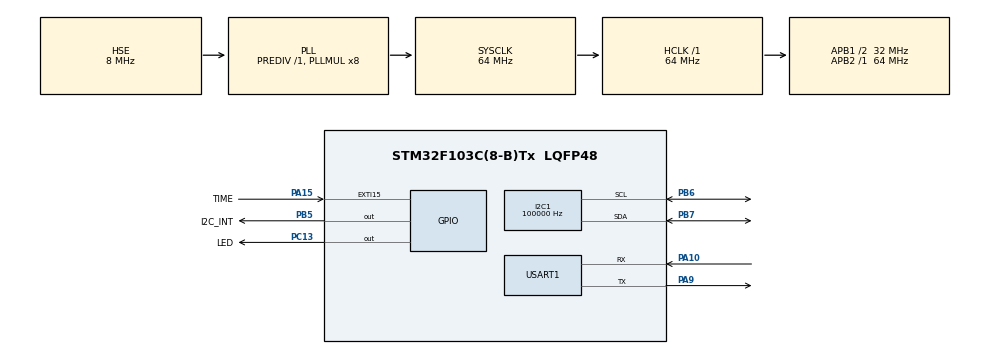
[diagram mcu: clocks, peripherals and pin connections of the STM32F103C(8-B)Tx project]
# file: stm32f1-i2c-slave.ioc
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Mcu.Family=STM32F1
Dma.USART1_TX.2.Direction=DMA_MEMORY_TO_PERIPH
NVIC.DMA1_Channel5_IRQn=true\:0\:0\:false\:false\:true\:false\:true
NVIC.I2C1_EV_IRQn=true\:0\:0\:false\:false\:true\:true\:true
Dma.I2C1_TX.1.Mode=DMA_NORMAL
VP_RTC_VS_RTC_Activate.Mode=RTC_Enabled
Dma.USART1_RX.3.MemDataAlignment=DMA_MDATAALIGN_BYTE
RCC.SYSCLKSource=RCC_SYSCLKSOURCE_PLLCLK
ProjectManager.StackSize=0x400
PD1-OSC_OUT.Signal=RCC_OSC_OUT
Dma.I2C1_TX.1.Direction=DMA_MEMORY_TO_PERIPH
PA15.GPIO_Label=TIME
I2C1.ClockSpeed=100000
PA15.GPIO_ModeDefaultEXTI=GPIO_MODE_IT_FALLING
RCC.HCLKFreq_Value=64000000
RCC.APB2TimFreq_Value=64000000
PB6.Signal=I2C1_SCL
PB5.PinState=GPIO_PIN_SET
Dma.I2C1_RX.0.PeriphDataAlignment=DMA_PDATAALIGN_BYTE
PB6.Mode=I2C
Dma.I2C1_TX.1.PeriphInc=DMA_PINC_DISABLE
RCC.AHBFreq_Value=64000000
Dma.I2C1_RX.0.Priority=DMA_PRIORITY_HIGH
NVIC.EXTI15_10_IRQn=true\:0\:0\:false\:false\:true\:true\:true
Dma.I2C1_RX.0.Mode=DMA_NORMAL
RCC.RTCClockSelection=RCC_RTCCLKSOURCE_LSE
RCC.PLLMUL=RCC_PLL_MUL8
I2C1.NoStretchMode=I2C_NOSTRETCH_DISABLE
PC14-OSC32_IN.Mode=LSE-External-Oscillator
PC13-TAMPER-RTC.PinState=GPIO_PIN_SET
PA14.Mode=Serial_Wire
Dma.USART1_TX.2.PeriphDataAlignment=DMA_PDATAALIGN_BYTE
PB7.Signal=I2C1_SDA
Dma.USART1_RX.3.Direction=DMA_PERIPH_TO_MEMORY
Dma.I2C1_RX.0.Direction=DMA_PERIPH_TO_MEMORY
PC13-TAMPER-RTC.GPIO_Speed=GPIO_SPEED_FREQ_HIGH
Dma.USART1_TX.2.MemDataAlignment=DMA_MDATAALIGN_BYTE
NVIC.I2C1_ER_IRQn=true\:0\:0\:false\:false\:true\:true\:true
Mcu.Package=LQFP48
Dma.USART1_RX.3.Instance=DMA1_Channel5
PA10.Signal=USART1_RX
PA15.Signal=GPXTI15
PB5.GPIO_Speed=GPIO_SPEED_FREQ_HIGH
PB5.GPIO_Label=I2C_INT
Dma.Request2=USART1_TX
Dma.Request1=I2C1_TX
RCC.APB1TimFreq_Value=64000000
Dma.Request3=USART1_RX
NVIC.DMA1_Channel4_IRQn=true\:0\:0\:false\:false\:true\:false\:true
RTC.AutoPrediv=RTC_AUTO_1_SECOND
NVIC.USART1_IRQn=true\:0\:0\:false\:false\:true\:true\:true
Dma.Request0=I2C1_RX
Dma.USART1_RX.3.MemInc=DMA_MINC_ENABLE
Dma.I2C1_TX.1.PeriphDataAlignment=DMA_PDATAALIGN_BYTE
RCC.PLLSourceVirtual=RCC_PLLSOURCE_HSE
PB5.GPIO_ModeDefaultOutputPP=GPIO_MODE_OUTPUT_OD
PC15-OSC32_OUT.Mode=LSE-External-Oscillator
NVIC.DMA1_Channel6_IRQn=true\:0\:0\:false\:false\:true\:false\:true
Dma.I2C1_RX.0.PeriphInc=DMA_PINC_DISABLE
Dma.I2C1_RX.0.MemDataAlignment=DMA_MDATAALIGN_BYTE
PD1-OSC_OUT.Mode=HSE-External-Oscillator
PA10.Mode=Asynchronous
Dma.USART1_TX.2.MemInc=DMA_MINC_ENABLE
Dma.USART1_RX.3.PeriphInc=DMA_PINC_DISABLE
PC13-TAMPER-RTC.Signal=GPIO_Output
PD0-OSC_IN.Signal=RCC_OSC_IN
RCC.APB1CLKDivider=RCC_HCLK_DIV2
PC14-OSC32_IN.Signal=RCC_OSC32_IN
I2C1.DualAddressMode=I2C_DUALADDRESS_DISABLE
PA13.Signal=SYS_JTMS-SWDIO
PA9.Mode=Asynchronous
ProjectManager.TargetToolchain=STM32CubeIDE
PA9.Signal=USART1_TX
Dma.I2C1_RX.0.MemInc=DMA_MINC_ENABLE
Dma.I2C1_TX.1.Instance=DMA1_Channel6
RCC.USBFreq_Value=64000000
PC15-OSC32_OUT.Signal=RCC_OSC32_OUT
PD0-OSC_IN.Mode=HSE-External-Oscillator
board=custom
Dma.I2C1_TX.1.Priority=DMA_PRIORITY_HIGH
PC13-TAMPER-RTC.GPIO_Label=LED
RCC.APB2Freq_Value=64000000
Dma.I2C1_TX.1.MemInc=DMA_MINC_ENABLE
Dma.USART1_TX.2.Priority=DMA_PRIORITY_LOW
Dma.I2C1_TX.1.MemDataAlignment=DMA_MDATAALIGN_BYTE
Dma.USART1_RX.3.PeriphDataAlignment=DMA_PDATAALIGN_BYTE
PA13.Mode=Serial_Wire
Mcu.Name=STM32F103C(8-B)Tx
Dma.USART1_RX.3.Priority=DMA_PRIORITY_LOW
Dma.USART1_TX.2.PeriphInc=DMA_PINC_DISABLE
I2C1.OwnAddress=0x68
RCC.SYSCLKFreq_VALUE=64000000
PC13-TAMPER-RTC.GPIO_ModeDefaultOutputPP=GPIO_MODE_OUTPUT_OD
PB5.Signal=GPIO_Output
PB5.GPIO_PuPd=GPIO_PULLUP
USART1.VirtualMode=VM_ASYNC
PB7.Mode=I2C
PA14.Signal=SYS_JTCK-SWCLK
ProjectManager.HeapSize=0x200
Dma.USART1_TX.2.Mode=DMA_NORMAL
NVIC.PriorityGroup=NVIC_PRIORITYGROUP_4
Dma.USART1_TX.2.Instance=DMA1_Channel4
NVIC.DMA1_Channel7_IRQn=true\:0\:0\:false\:false\:true\:false\:true
RCC.APB1Freq_Value=32000000
Dma.USART1_RX.3.Mode=DMA_NORMAL
Dma.I2C1_RX.0.Instance=DMA1_Channel7

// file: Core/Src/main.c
/* USER CODE BEGIN Header */
/**
  ******************************************************************************
  * @file           : main.c
  * @brief          : Main program body
  ******************************************************************************
  * @attention
  *
  * <h2><center>&copy; Copyright (c) 2020 STMicroelectronics.
  * All rights reserved.</center></h2>
  *
  * This software component is licensed by ST under BSD 3-Clause license,
  * the "License"; You may not use this file except in compliance with the
  * License. You may obtain a copy of the License at:
  *                        opensource.org/licenses/BSD-3-Clause
  *
  ******************************************************************************
  */
/* USER CODE END Header */
#include "main.h"

UART_HandleTypeDef huart1;
DMA_HandleTypeDef hdma_usart1_tx;
DMA_HandleTypeDef hdma_usart1_rx;

void SystemClock_Config(void);
static void MX_GPIO_Init(void);
static void MX_DMA_Init(void);
static void MX_I2C1_Init(void);
static void MX_USART1_UART_Init(void);
static void MX_RTC_Init(void);

/* USER CODE BEGIN 0 */

extern void initialise_monitor_handles(void);
int app_main();
/* USER CODE END 0 */

int main(void)
{
  /* USER CODE BEGIN 1 */
  initialise_monitor_handles();
  /* USER CODE END 1 */

  /* MCU Configuration--------------------------------------------------------*/

  /* Reset of all peripherals, Initializes the Flash interface and the Systick. */
  HAL_Init();

  /* Configure the system clock */
  SystemClock_Config();

  /* Initialize all configured peripherals */
  MX_GPIO_Init();
  MX_DMA_Init();
  MX_I2C1_Init();
  MX_USART1_UART_Init();
  MX_RTC_Init();
  /* USER CODE BEGIN 2 */
  app_main();
  /* USER CODE END 2 */

  /* Infinite loop */

}

void SystemClock_Config(void)
{
  RCC_OscInitTypeDef RCC_OscInitStruct = {0};
  RCC_ClkInitTypeDef RCC_ClkInitStruct = {0};
  RCC_PeriphCLKInitTypeDef PeriphClkInit = {0};

  /** Initializes the RCC Oscillators according to the specified parameters
  * in the RCC_OscInitTypeDef structure.
  */
  RCC_OscInitStruct.OscillatorType = RCC_OSCILLATORTYPE_HSE|RCC_OSCILLATORTYPE_LSE;
  RCC_OscInitStruct.HSEState = RCC_HSE_ON;
  RCC_OscInitStruct.HSEPredivValue = RCC_HSE_PREDIV_DIV1;
  RCC_OscInitStruct.LSEState = RCC_LSE_ON;
  RCC_OscInitStruct.HSIState = RCC_HSI_ON;
  RCC_OscInitStruct.PLL.PLLState = RCC_PLL_ON;
  RCC_OscInitStruct.PLL.PLLSource = RCC_PLLSOURCE_HSE;
  RCC_OscInitStruct.PLL.PLLMUL = RCC_PLL_MUL8;
  if (HAL_RCC_OscConfig(&RCC_OscInitStruct) != HAL_OK)
  {
    Error_Handler();
  }
  /** Initializes the CPU, AHB and APB buses clocks
  */
  RCC_ClkInitStruct.ClockType = RCC_CLOCKTYPE_HCLK|RCC_CLOCKTYPE_SYSCLK
                              |RCC_CLOCKTYPE_PCLK1|RCC_CLOCKTYPE_PCLK2;
  RCC_ClkInitStruct.SYSCLKSource = RCC_SYSCLKSOURCE_PLLCLK;
  RCC_ClkInitStruct.AHBCLKDivider = RCC_SYSCLK_DIV1;
  RCC_ClkInitStruct.APB1CLKDivider = RCC_HCLK_DIV2;
  RCC_ClkInitStruct.APB2CLKDivider = RCC_HCLK_DIV1;

  if (HAL_RCC_ClockConfig(&RCC_ClkInitStruct, FLASH_LATENCY_2) != HAL_OK)
  {
    Error_Handler();
  }
  PeriphClkInit.PeriphClockSelection = RCC_PERIPHCLK_RTC;
  PeriphClkInit.RTCClockSelection = RCC_RTCCLKSOURCE_LSE;
  if (HAL_RCCEx_PeriphCLKConfig(&PeriphClkInit) != HAL_OK)
  {
    Error_Handler();
  }
}

static void MX_I2C1_Init(void)
{

  LL_I2C_InitTypeDef I2C_InitStruct = {0};

  LL_GPIO_InitTypeDef GPIO_InitStruct = {0};

  LL_APB2_GRP1_EnableClock(LL_APB2_GRP1_PERIPH_GPIOB);
  /**I2C1 GPIO Configuration
  PB6   ------> I2C1_SCL
  PB7   ------> I2C1_SDA
  */
  GPIO_InitStruct.Pin = LL_GPIO_PIN_6|LL_GPIO_PIN_7;
  GPIO_InitStruct.Mode = LL_GPIO_MODE_ALTERNATE;
  GPIO_InitStruct.Speed = LL_GPIO_SPEED_FREQ_HIGH;
  GPIO_InitStruct.OutputType = LL_GPIO_OUTPUT_OPENDRAIN;
  LL_GPIO_Init(GPIOB, &GPIO_InitStruct);

  /* Peripheral clock enable */
  LL_APB1_GRP1_EnableClock(LL_APB1_GRP1_PERIPH_I2C1);

  /* I2C1 DMA Init */

  /* I2C1_RX Init */
  LL_DMA_SetDataTransferDirection(DMA1, LL_DMA_CHANNEL_7, LL_DMA_DIRECTION_PERIPH_TO_MEMORY);

  LL_DMA_SetChannelPriorityLevel(DMA1, LL_DMA_CHANNEL_7, LL_DMA_PRIORITY_HIGH);

  LL_DMA_SetMode(DMA1, LL_DMA_CHANNEL_7, LL_DMA_MODE_NORMAL);

  LL_DMA_SetPeriphIncMode(DMA1, LL_DMA_CHANNEL_7, LL_DMA_PERIPH_NOINCREMENT);

  LL_DMA_SetMemoryIncMode(DMA1, LL_DMA_CHANNEL_7, LL_DMA_MEMORY_INCREMENT);

  LL_DMA_SetPeriphSize(DMA1, LL_DMA_CHANNEL_7, LL_DMA_PDATAALIGN_BYTE);

  LL_DMA_SetMemorySize(DMA1, LL_DMA_CHANNEL_7, LL_DMA_MDATAALIGN_BYTE);

  /* I2C1_TX Init */
  LL_DMA_SetDataTransferDirection(DMA1, LL_DMA_CHANNEL_6, LL_DMA_DIRECTION_MEMORY_TO_PERIPH);

  LL_DMA_SetChannelPriorityLevel(DMA1, LL_DMA_CHANNEL_6, LL_DMA_PRIORITY_HIGH);

  LL_DMA_SetMode(DMA1, LL_DMA_CHANNEL_6, LL_DMA_MODE_NORMAL);

  LL_DMA_SetPeriphIncMode(DMA1, LL_DMA_CHANNEL_6, LL_DMA_PERIPH_NOINCREMENT);

  LL_DMA_SetMemoryIncMode(DMA1, LL_DMA_CHANNEL_6, LL_DMA_MEMORY_INCREMENT);

  LL_DMA_SetPeriphSize(DMA1, LL_DMA_CHANNEL_6, LL_DMA_PDATAALIGN_BYTE);

  LL_DMA_SetMemorySize(DMA1, LL_DMA_CHANNEL_6, LL_DMA_MDATAALIGN_BYTE);

  /* I2C1 interrupt Init */
  NVIC_SetPriority(I2C1_EV_IRQn, NVIC_EncodePriority(NVIC_GetPriorityGrouping(),0, 0));
  NVIC_EnableIRQ(I2C1_EV_IRQn);
  NVIC_SetPriority(I2C1_ER_IRQn, NVIC_EncodePriority(NVIC_GetPriorityGrouping(),0, 0));
  NVIC_EnableIRQ(I2C1_ER_IRQn);

  /** I2C Initialization
  */
  LL_I2C_DisableOwnAddress2(I2C1);
  LL_I2C_DisableGeneralCall(I2C1);
  LL_I2C_EnableClockStretching(I2C1);
  I2C_InitStruct.PeripheralMode = LL_I2C_MODE_I2C;
  I2C_InitStruct.ClockSpeed = 100000;
  I2C_InitStruct.DutyCycle = LL_I2C_DUTYCYCLE_2;
  I2C_InitStruct.OwnAddress1 = 208;
  I2C_InitStruct.TypeAcknowledge = LL_I2C_ACK;
  I2C_InitStruct.OwnAddrSize = LL_I2C_OWNADDRESS1_7BIT;
  LL_I2C_Init(I2C1, &I2C_InitStruct);
  LL_I2C_SetOwnAddress2(I2C1, 0);

}

static void MX_RTC_Init(void)
{

  LL_RTC_InitTypeDef RTC_InitStruct = {0};

    LL_PWR_EnableBkUpAccess();
    /* Enable BKP CLK enable for backup registers */
    LL_APB1_GRP1_EnableClock(LL_APB1_GRP1_PERIPH_BKP);
  /* Peripheral clock enable */
  LL_RCC_EnableRTC();

  /** Initialize RTC and set the Time and Date
  */
  RTC_InitStruct.AsynchPrescaler = 0xFFFFFFFFU;
  LL_RTC_Init(RTC, &RTC_InitStruct);
  LL_RTC_SetAsynchPrescaler(RTC, 0xFFFFFFFFU);

}

static void MX_USART1_UART_Init(void)
{

  huart1.Instance = USART1;
  huart1.Init.BaudRate = 115200;
  huart1.Init.WordLength = UART_WORDLENGTH_8B;
  huart1.Init.StopBits = UART_STOPBITS_1;
  huart1.Init.Parity = UART_PARITY_NONE;
  huart1.Init.Mode = UART_MODE_TX_RX;
  huart1.Init.HwFlowCtl = UART_HWCONTROL_NONE;
  huart1.Init.OverSampling = UART_OVERSAMPLING_16;
  if (HAL_UART_Init(&huart1) != HAL_OK)
  {
    Error_Handler();
  }

}

static void MX_DMA_Init(void)
{

  /* DMA controller clock enable */
  __HAL_RCC_DMA1_CLK_ENABLE();

  /* DMA interrupt init */
  /* DMA1_Channel4_IRQn interrupt configuration */
  HAL_NVIC_SetPriority(DMA1_Channel4_IRQn, 0, 0);
  HAL_NVIC_EnableIRQ(DMA1_Channel4_IRQn);
  /* DMA1_Channel5_IRQn interrupt configuration */
  HAL_NVIC_SetPriority(DMA1_Channel5_IRQn, 0, 0);
  HAL_NVIC_EnableIRQ(DMA1_Channel5_IRQn);
  /* DMA1_Channel6_IRQn interrupt configuration */
  NVIC_SetPriority(DMA1_Channel6_IRQn, NVIC_EncodePriority(NVIC_GetPriorityGrouping(),0, 0));
  NVIC_EnableIRQ(DMA1_Channel6_IRQn);
  /* DMA1_Channel7_IRQn interrupt configuration */
  NVIC_SetPriority(DMA1_Channel7_IRQn, NVIC_EncodePriority(NVIC_GetPriorityGrouping(),0, 0));
  NVIC_EnableIRQ(DMA1_Channel7_IRQn);

}

static void MX_GPIO_Init(void)
{
  GPIO_InitTypeDef GPIO_InitStruct = {0};

  /* GPIO Ports Clock Enable */
  __HAL_RCC_GPIOC_CLK_ENABLE();
  __HAL_RCC_GPIOD_CLK_ENABLE();
  __HAL_RCC_GPIOA_CLK_ENABLE();
  __HAL_RCC_GPIOB_CLK_ENABLE();

  /*Configure GPIO pin Output Level */
  HAL_GPIO_WritePin(LED_GPIO_Port, LED_Pin, GPIO_PIN_SET);

  /*Configure GPIO pin Output Level */
  HAL_GPIO_WritePin(I2C_INT_GPIO_Port, I2C_INT_Pin, GPIO_PIN_SET);

  /*Configure GPIO pin : LED_Pin */
  GPIO_InitStruct.Pin = LED_Pin;
  GPIO_InitStruct.Mode = GPIO_MODE_OUTPUT_OD;
  GPIO_InitStruct.Pull = GPIO_NOPULL;
  GPIO_InitStruct.Speed = GPIO_SPEED_FREQ_HIGH;
  HAL_GPIO_Init(LED_GPIO_Port, &GPIO_InitStruct);

  /*Configure GPIO pin : TIME_Pin */
  GPIO_InitStruct.Pin = TIME_Pin;
  GPIO_InitStruct.Mode = GPIO_MODE_IT_FALLING;
  GPIO_InitStruct.Pull = GPIO_NOPULL;
  HAL_GPIO_Init(TIME_GPIO_Port, &GPIO_InitStruct);

  /*Configure GPIO pin : I2C_INT_Pin */
  GPIO_InitStruct.Pin = I2C_INT_Pin;
  GPIO_InitStruct.Mode = GPIO_MODE_OUTPUT_OD;
  GPIO_InitStruct.Pull = GPIO_PULLUP;
  GPIO_InitStruct.Speed = GPIO_SPEED_FREQ_HIGH;
  HAL_GPIO_Init(I2C_INT_GPIO_Port, &GPIO_InitStruct);

  /* EXTI interrupt init*/
  HAL_NVIC_SetPriority(EXTI15_10_IRQn, 0, 0);
  HAL_NVIC_EnableIRQ(EXTI15_10_IRQn);

}

void Error_Handler(void)
{
}

/************************ (C) COPYRIGHT STMicroelectronics *****END OF FILE****/
